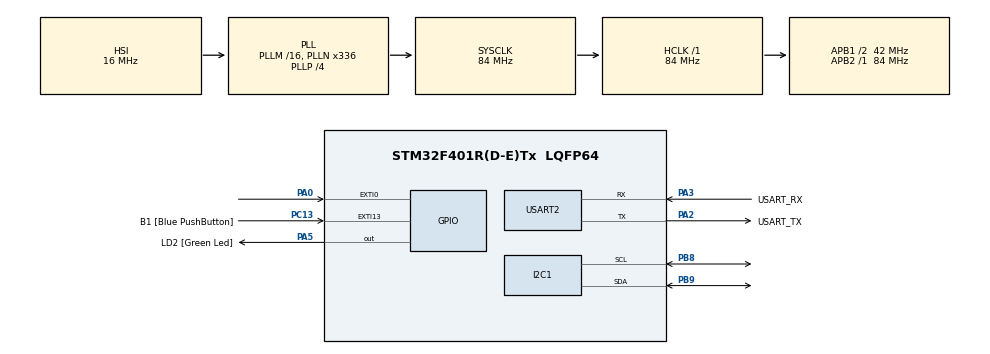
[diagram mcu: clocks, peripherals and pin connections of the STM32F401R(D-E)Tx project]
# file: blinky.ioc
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I2C1.I2C_Mode=I2C_Standard
Mcu.Family=STM32F4
Mcu.Name=STM32F401R(D-E)Tx
Mcu.Package=LQFP64
NVIC.EXTI0_IRQn=true\:0\:0\:false\:false\:true\:true\:true\:true
NVIC.PriorityGroup=NVIC_PRIORITYGROUP_4
PA0-WKUP.GPIO_PuPd=GPIO_PULLDOWN
PA0-WKUP.Signal=GPXTI0
PA13.GPIO_Label=TMS
PA13.Mode=Trace_Asynchronous_SW
PA13.Signal=SYS_JTMS-SWDIO
PA14.GPIO_Label=TCK
PA14.Mode=Trace_Asynchronous_SW
PA14.Signal=SYS_JTCK-SWCLK
PA2.GPIO_Label=USART_TX
PA2.GPIO_Mode=GPIO_MODE_AF_PP
PA2.GPIO_PuPd=GPIO_NOPULL
PA2.GPIO_Speed=GPIO_SPEED_FREQ_LOW
PA2.Mode=Asynchronous
PA2.Signal=USART2_TX
PA3.GPIO_Label=USART_RX
PA3.GPIO_Mode=GPIO_MODE_AF_PP
PA3.GPIO_PuPd=GPIO_NOPULL
PA3.GPIO_Speed=GPIO_SPEED_FREQ_LOW
PA3.Mode=Asynchronous
PA3.Signal=USART2_RX
PA5.GPIO_Label=LD2 [Green Led]
PA5.GPIO_Mode=GPIO_MODE_OUTPUT_PP
PA5.GPIO_PuPd=GPIO_NOPULL
PA5.GPIO_Speed=GPIO_SPEED_FREQ_LOW
PA5.Signal=GPIO_Output
PB3.GPIO_Label=SWO
PB3.Mode=Trace_Asynchronous_SW
PB3.Signal=SYS_JTDO-SWO
PB8.Mode=I2C
PB8.Signal=I2C1_SCL
PB9.Mode=I2C
PB9.Signal=I2C1_SDA
PC13-ANTI_TAMP.GPIO_Label=B1 [Blue PushButton]
PC13-ANTI_TAMP.GPIO_ModeDefaultEXTI=GPIO_MODE_IT_FALLING
PC13-ANTI_TAMP.GPIO_PuPd=GPIO_NOPULL
PC13-ANTI_TAMP.Signal=GPXTI13
PC14-OSC32_IN.Mode=LSE-External-Oscillator
PC14-OSC32_IN.Signal=RCC_OSC32_IN
PC15-OSC32_OUT.Mode=LSE-External-Oscillator
PC15-OSC32_OUT.Signal=RCC_OSC32_OUT
PH0\ -\ OSC_IN.Mode=HSE-External-Clock-Source
PH0\ -\ OSC_IN.Signal=RCC_OSC_IN
PH1\ -\ OSC_OUT.Mode=HSE-External-Clock-Source
PH1\ -\ OSC_OUT.Signal=RCC_OSC_OUT
ProjectManager.HeapSize=0x200
ProjectManager.StackSize=0x400
ProjectManager.TargetToolchain=Makefile
RCC.48MHZClocksFreq_Value=48000000
RCC.AHBFreq_Value=84000000
RCC.APB1CLKDivider=RCC_HCLK_DIV2
RCC.APB1Freq_Value=42000000
RCC.APB1TimFreq_Value=84000000
RCC.APB2Freq_Value=84000000
RCC.APB2TimFreq_Value=84000000
RCC.CortexFreq_Value=84000000
RCC.HCLKFreq_Value=84000000
RCC.HSE_VALUE=8000000
RCC.HSI_VALUE=16000000
RCC.PLLN=336
RCC.PLLP=RCC_PLLP_DIV4
RCC.PLLQ=7
RCC.SYSCLKFreq_VALUE=84000000
RCC.SYSCLKSource=RCC_SYSCLKSOURCE_PLLCLK
RCC.VCOOutputFreq_Value=336000000
USART2.VirtualMode=VM_ASYNC
board=NUCLEO-F401RE

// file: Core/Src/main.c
/* USER CODE BEGIN Header */
/**
  ******************************************************************************
  * @file           : main.c
  * @brief          : Main program body
  ******************************************************************************
  * @attention
  *
  * Copyright (c) 2026 STMicroelectronics.
  * All rights reserved.
  *
  * This software is licensed under terms that can be found in the LICENSE file
  * in the root directory of this software component.
  * If no LICENSE file comes with this software, it is provided AS-IS.
  *
  ******************************************************************************
  */
/* USER CODE END Header */
#include "main.h"
#include <math.h>
#include <string.h>

/* USER CODE BEGIN PD */
volatile uint8_t data_ready_flag = 0;
/* USER CODE END PD */

I2C_HandleTypeDef hi2c1;

UART_HandleTypeDef huart2;

/* USER CODE BEGIN PV */

struct State state = {0};

int16_t Accel_X, Accel_Y, Accel_Z;
int16_t Gyro_X, Gyro_Y, Gyro_Z;
int16_t Temp;

float a_x, a_y, a_z, g_x, g_y, g_z, tt;

/* USER CODE END PV */

void SystemClock_Config(void);
static void MX_GPIO_Init(void);
static void MX_USART2_UART_Init(void);
static void MX_I2C1_Init(void);

int main(void)
{

  /* MCU Configuration--------------------------------------------------------*/

  /* Reset of all peripherals, Initializes the Flash interface and the Systick. */
  HAL_Init();

  /* Configure the system clock */
  SystemClock_Config();

  /* Initialize all configured peripherals */
  MX_GPIO_Init();
  MX_USART2_UART_Init();
  MX_I2C1_Init();
  /* USER CODE BEGIN 2 */

  MPU6050_Init(&hi2c1);
  // void convert(int16_t *accel_x, int16_t *accel_y, int16_t *accel_z, int16_t *gyro_x, int16_t *gyro_y, int16_t *gyro_z, float *a_x, float *a_y, float *a_z, float *g_x, float *g_y, float *g_z);

  /* USER CODE END 2 */

  /* Infinite loop */
  while (1)
  {

    float A_X_Arr[WINDOW_SIZE];
    float A_Y_Arr[WINDOW_SIZE];
    float A_Z_Arr[WINDOW_SIZE];
    float G_X_Arr[WINDOW_SIZE];
    float G_Y_Arr[WINDOW_SIZE];
    float G_Z_Arr[WINDOW_SIZE];
    float Temp_Arr[WINDOW_SIZE];

    // Window to take median and mean
    for(int i = 0; i < WINDOW_SIZE;){

      while(!data_ready_flag){ __WFI(); }
      data_ready_flag = 0;

      uint8_t buffer[14];
      if(HAL_I2C_Mem_Read(&hi2c1, MPU6050_ADDR, REG_ACCEL_XOUT_H, 1, buffer, 14, 1) != HAL_OK){
        continue;
      }

      set_bits(buffer, &Accel_X, &Accel_Y, &Accel_Z, &Temp, &Gyro_X, &Gyro_Y, &Gyro_Z);
      convert_accel_and_temp(&Accel_X, &Accel_Y, &Accel_Z, &Temp, &a_x, &a_y, &a_z, &tt);
      convert_gyro(&Gyro_X, &Gyro_Y, &Gyro_Z, &g_x, &g_y, &g_z);
      append_values(A_X_Arr, A_Y_Arr, A_Z_Arr, Temp_Arr, G_X_Arr, G_Y_Arr, G_Z_Arr, &a_x, &a_y, &a_z, &tt, &g_x, &g_y, &g_z, i);

      i++; // only move on with a good sample
    }

    update_state(A_X_Arr, A_Y_Arr, A_Z_Arr, Temp_Arr, G_X_Arr, G_Y_Arr, G_Z_Arr, &state);

    // calculates the time passage to interate the gyroscope
    update_roll_pitch_yaw(&state, DT);

    uint8_t state_buffer[12];
    memcpy(&state_buffer[0], &state.roll, 4);
    memcpy(&state_buffer[4], &state.pitch, 4);
    memcpy(&state_buffer[8], &state.yaw, 4);

    HAL_UART_Transmit(&huart2, state_buffer, 12, 100);

    HAL_GPIO_TogglePin(GPIOA, GPIO_PIN_5);

        // printf("Accel_X: %d | Accel_Y: %d | Accel_Z: %d | Gyro_X: %d | Gyro_Y: %d | Gyro_Z: %d | Temp: %d\r\n", Accel_X, Accel_Y, Accel_Z, Gyro_X, Gyro_Y, Gyro_Z, Temp);

  }
}

void SystemClock_Config(void)
{
  RCC_OscInitTypeDef RCC_OscInitStruct = {0};
  RCC_ClkInitTypeDef RCC_ClkInitStruct = {0};

  /** Configure the main internal regulator output voltage
  */
  __HAL_RCC_PWR_CLK_ENABLE();
  __HAL_PWR_VOLTAGESCALING_CONFIG(PWR_REGULATOR_VOLTAGE_SCALE2);

  /** Initializes the RCC Oscillators according to the specified parameters
  * in the RCC_OscInitTypeDef structure.
  */
  RCC_OscInitStruct.OscillatorType = RCC_OSCILLATORTYPE_HSI;
  RCC_OscInitStruct.HSIState = RCC_HSI_ON;
  RCC_OscInitStruct.HSICalibrationValue = RCC_HSICALIBRATION_DEFAULT;
  RCC_OscInitStruct.PLL.PLLState = RCC_PLL_ON;
  RCC_OscInitStruct.PLL.PLLSource = RCC_PLLSOURCE_HSI;
  RCC_OscInitStruct.PLL.PLLM = 16;
  RCC_OscInitStruct.PLL.PLLN = 336;
  RCC_OscInitStruct.PLL.PLLP = RCC_PLLP_DIV4;
  RCC_OscInitStruct.PLL.PLLQ = 7;
  if (HAL_RCC_OscConfig(&RCC_OscInitStruct) != HAL_OK)
  {
    Error_Handler();
  }

  /** Initializes the CPU, AHB and APB buses clocks
  */
  RCC_ClkInitStruct.ClockType = RCC_CLOCKTYPE_HCLK|RCC_CLOCKTYPE_SYSCLK
                              |RCC_CLOCKTYPE_PCLK1|RCC_CLOCKTYPE_PCLK2;
  RCC_ClkInitStruct.SYSCLKSource = RCC_SYSCLKSOURCE_PLLCLK;
  RCC_ClkInitStruct.AHBCLKDivider = RCC_SYSCLK_DIV1;
  RCC_ClkInitStruct.APB1CLKDivider = RCC_HCLK_DIV2;
  RCC_ClkInitStruct.APB2CLKDivider = RCC_HCLK_DIV1;

  if (HAL_RCC_ClockConfig(&RCC_ClkInitStruct, FLASH_LATENCY_2) != HAL_OK)
  {
    Error_Handler();
  }
}

static void MX_I2C1_Init(void)
{

  hi2c1.Instance = I2C1;
  hi2c1.Init.ClockSpeed = 400000;
  hi2c1.Init.DutyCycle = I2C_DUTYCYCLE_2;
  hi2c1.Init.OwnAddress1 = 0;
  hi2c1.Init.AddressingMode = I2C_ADDRESSINGMODE_7BIT;
  hi2c1.Init.DualAddressMode = I2C_DUALADDRESS_DISABLE;
  hi2c1.Init.OwnAddress2 = 0;
  hi2c1.Init.GeneralCallMode = I2C_GENERALCALL_DISABLE;
  hi2c1.Init.NoStretchMode = I2C_NOSTRETCH_DISABLE;
  if (HAL_I2C_Init(&hi2c1) != HAL_OK)
  {
    Error_Handler();
  }

}

static void MX_USART2_UART_Init(void)
{

  huart2.Instance = USART2;
  huart2.Init.BaudRate = 115200;
  huart2.Init.WordLength = UART_WORDLENGTH_8B;
  huart2.Init.StopBits = UART_STOPBITS_1;
  huart2.Init.Parity = UART_PARITY_NONE;
  huart2.Init.Mode = UART_MODE_TX_RX;
  huart2.Init.HwFlowCtl = UART_HWCONTROL_NONE;
  huart2.Init.OverSampling = UART_OVERSAMPLING_16;
  if (HAL_UART_Init(&huart2) != HAL_OK)
  {
    Error_Handler();
  }

}

static void MX_GPIO_Init(void)
{
  GPIO_InitTypeDef GPIO_InitStruct = {0};

  /* GPIO Ports Clock Enable */
  __HAL_RCC_GPIOC_CLK_ENABLE();
  __HAL_RCC_GPIOH_CLK_ENABLE();
  __HAL_RCC_GPIOA_CLK_ENABLE();
  __HAL_RCC_GPIOB_CLK_ENABLE();

  /*Configure GPIO pin Output Level */
  HAL_GPIO_WritePin(LD2_GPIO_Port, LD2_Pin, GPIO_PIN_RESET);

  /*Configure GPIO pin : B1_Pin */
  GPIO_InitStruct.Pin = B1_Pin;
  GPIO_InitStruct.Mode = GPIO_MODE_INPUT;
  GPIO_InitStruct.Pull = GPIO_NOPULL;
  HAL_GPIO_Init(B1_GPIO_Port, &GPIO_InitStruct);

  /*Configure GPIO pin : PA0 */
  GPIO_InitStruct.Pin = GPIO_PIN_0;
  GPIO_InitStruct.Mode = GPIO_MODE_IT_RISING;
  GPIO_InitStruct.Pull = GPIO_PULLDOWN;
  HAL_GPIO_Init(GPIOA, &GPIO_InitStruct);

  /*Configure GPIO pin : LD2_Pin */
  GPIO_InitStruct.Pin = LD2_Pin;
  GPIO_InitStruct.Mode = GPIO_MODE_OUTPUT_PP;
  GPIO_InitStruct.Pull = GPIO_NOPULL;
  GPIO_InitStruct.Speed = GPIO_SPEED_FREQ_LOW;
  HAL_GPIO_Init(LD2_GPIO_Port, &GPIO_InitStruct);

  /* EXTI interrupt init*/
  HAL_NVIC_SetPriority(EXTI0_IRQn, 0, 0);
  HAL_NVIC_EnableIRQ(EXTI0_IRQn);

}

/* USER CODE BEGIN 4 */

void HAL_GPIO_EXTI_Callback(uint16_t GPIO_Pin)
{
  if (GPIO_Pin == GPIO_PIN_0){
    data_ready_flag = 1;
  }
}

/* USER CODE END 4 */

void Error_Handler(void)
{
  __disable_irq();
  while (1)
  {
  }
}
